# BL808 register map
File version: 0.1
Registers are access not given, no defined reset value unless marked. A register's access mark holds for its fields unless they carry their own. Offsets are from the block's base; [hi:lo] are bit positions; {n}, {i} and the like mark numbered series.

## USB
Base 0x02007200
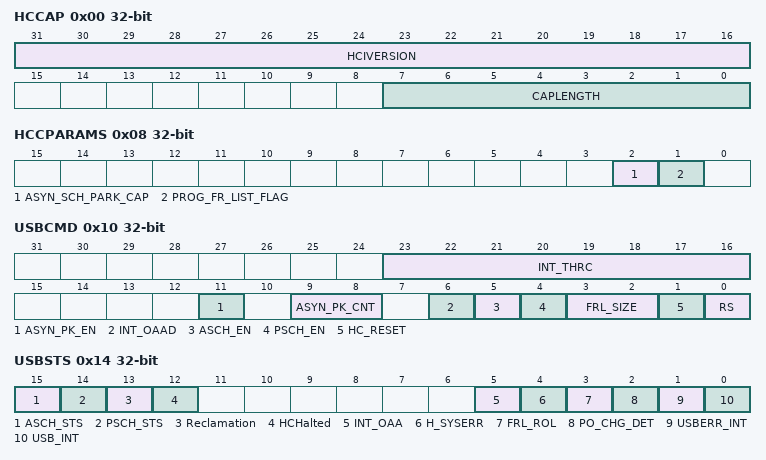
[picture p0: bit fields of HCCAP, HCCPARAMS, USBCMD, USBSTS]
0x00 HCCAP
  [31:16] HCIVERSION, [7:0] CAPLENGTH
0x04 HCSPARAMS
  [3:0] N_PORTS
0x08 HCCPARAMS
  [2] ASYN_SCH_PARK_CAP, [1] PROG_FR_LIST_FLAG
0x10 USBCMD
  [23:16] INT_THRC, [11] ASYN_PK_EN, [9:8] ASYN_PK_CNT, [6] INT_OAAD, [5] ASCH_EN, [4] PSCH_EN, [3:2] FRL_SIZE, [1] HC_RESET, [0] RS
0x14 USBSTS
  [15] ASCH_STS, [14] PSCH_STS, [13] Reclamation, [12] HCHalted, [5] INT_OAA, [4] H_SYSERR, [3] FRL_ROL, [2] PO_CHG_DET, [1] USBERR_INT, [0] USB_INT
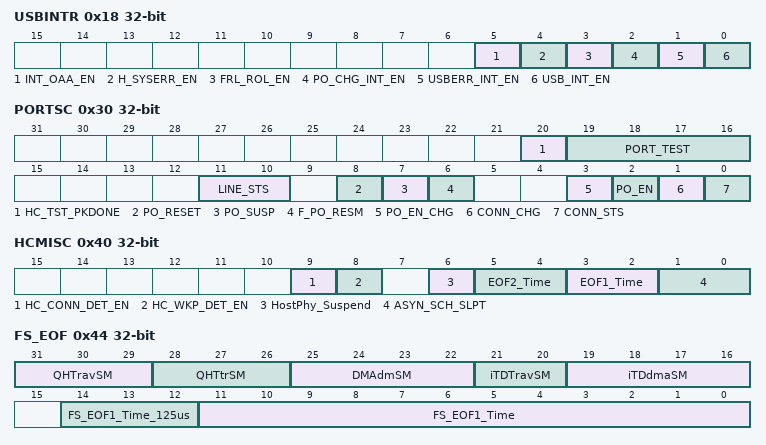
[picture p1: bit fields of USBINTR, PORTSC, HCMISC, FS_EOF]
0x18 USBINTR
  [5] INT_OAA_EN, [4] H_SYSERR_EN, [3] FRL_ROL_EN, [2] PO_CHG_INT_EN, [1] USBERR_INT_EN, [0] USB_INT_EN
0x1C FRINDEX
  [13:0] FRINDEX
0x24 PERIODICLISTBASE
  [31:12] PERI_BASADR
0x28 ASYNCLISTADDR
  [31:5] Async_ladr
0x30 PORTSC
  [20] HC_TST_PKDONE, [19:16] PORT_TEST, [11:10] LINE_STS, [8] PO_RESET, [7] PO_SUSP, [6] F_PO_RESM, [3] PO_EN_CHG, [2] PO_EN, [1] CONN_CHG, [0] CONN_STS
0x40 HCMISC
  [9] HC_CONN_DET_EN, [8] HC_WKP_DET_EN, [6] HostPhy_Suspend, [5:4] EOF2_Time, [3:2] EOF1_Time, [1:0] ASYN_SCH_SLPT
0x44 FS_EOF
  [31:29] QHTravSM, [28:26] QHTtrSM, [25:22] DMAdmSM, [21:20] iTDTravSM, [19:16] iTDdmaSM, [14:12] FS_EOF1_Time_125us, [11:0] FS_EOF1_Time
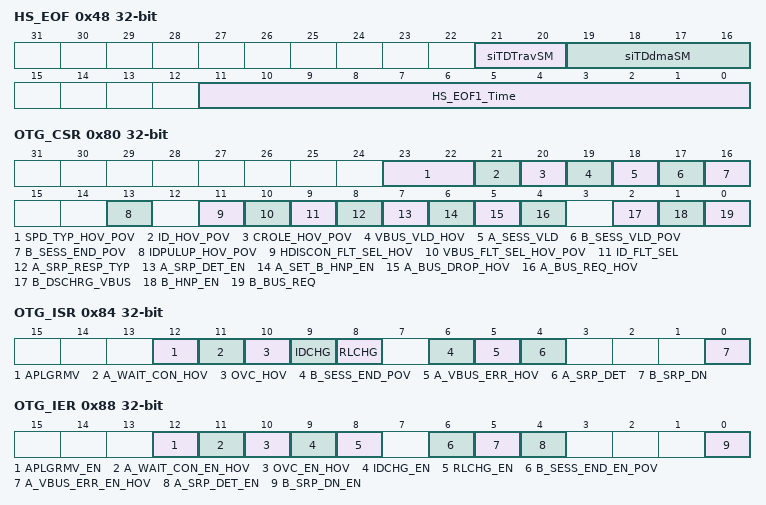
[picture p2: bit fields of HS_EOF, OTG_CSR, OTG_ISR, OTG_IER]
0x48 HS_EOF
  [21:20] siTDTravSM, [19:16] siTDdmaSM, [11:0] HS_EOF1_Time
0x80 OTG_CSR
  [23:22] SPD_TYP_HOV_POV, [21] ID_HOV_POV, [20] CROLE_HOV_POV, [19] VBUS_VLD_HOV, [18] A_SESS_VLD, [17] B_SESS_VLD_POV, [16] B_SESS_END_POV, [13] IDPULUP_HOV_POV, [11] HDISCON_FLT_SEL_HOV, [10] VBUS_FLT_SEL_HOV_POV, [9] ID_FLT_SEL, [8] A_SRP_RESP_TYP, [7] A_SRP_DET_EN, [6] A_SET_B_HNP_EN, [5] A_BUS_DROP_HOV, [4] A_BUS_REQ_HOV, [2] B_DSCHRG_VBUS, [1] B_HNP_EN, [0] B_BUS_REQ
0x84 OTG_ISR
  [12] APLGRMV, [11] A_WAIT_CON_HOV, [10] OVC_HOV, [9] IDCHG, [8] RLCHG, [6] B_SESS_END_POV, [5] A_VBUS_ERR_HOV, [4] A_SRP_DET, [0] B_SRP_DN
0x88 OTG_IER
  [12] APLGRMV_EN, [11] A_WAIT_CON_EN_HOV, [10] OVC_EN_HOV, [9] IDCHG_EN, [8] RLCHG_EN, [6] B_SESS_END_EN_POV, [5] A_VBUS_ERR_EN_HOV, [4] A_SRP_DET_EN, [0] B_SRP_DN_EN
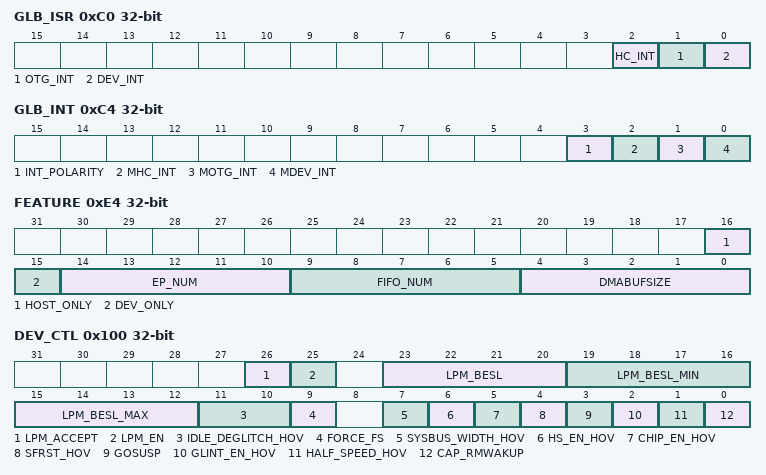
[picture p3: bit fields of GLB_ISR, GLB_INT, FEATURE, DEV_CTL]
0xC0 GLB_ISR
  [2] HC_INT, [1] OTG_INT, [0] DEV_INT
0xC4 GLB_INT
  [3] INT_POLARITY, [2] MHC_INT, [1] MOTG_INT, [0] MDEV_INT
0xE0 REVISION
  [31:0] REVISION
0xE4 FEATURE
  [16] HOST_ONLY, [15] DEV_ONLY, [14:10] EP_NUM, [9:5] FIFO_NUM, [4:0] DMABUFSIZE
0xE8 AXI_CR
  [0] AXI_SGLBST
0x100 DEV_CTL
  [26] LPM_ACCEPT, [25] LPM_EN, [23:20] LPM_BESL, [19:16] LPM_BESL_MIN, [15:12] LPM_BESL_MAX, [11:10] IDLE_DEGLITCH_HOV, [9] FORCE_FS, [7] SYSBUS_WIDTH_HOV, [6] HS_EN_HOV, [5] CHIP_EN_HOV, [4] SFRST_HOV, [3] GOSUSP, [2] GLINT_EN_HOV, [1] HALF_SPEED_HOV, [0] CAP_RMWAKUP
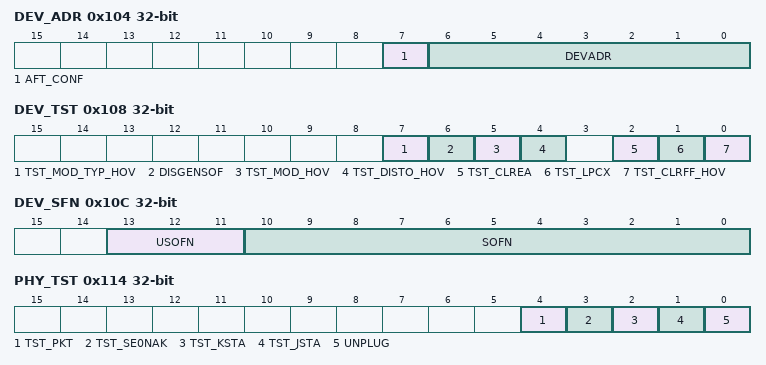
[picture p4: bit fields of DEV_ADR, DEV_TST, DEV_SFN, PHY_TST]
0x104 DEV_ADR
  [7] AFT_CONF, [6:0] DEVADR
0x108 DEV_TST
  [7] TST_MOD_TYP_HOV, [6] DISGENSOF, [5] TST_MOD_HOV, [4] TST_DISTO_HOV, [2] TST_CLREA, [1] TST_LPCX, [0] TST_CLRFF_HOV
0x10C DEV_SFN
  [13:11] USOFN, [10:0] SOFN
0x110 DEV_SMT
  [15:0] SOFMT
0x114 PHY_TST
  [4] TST_PKT, [3] TST_SE0NAK, [2] TST_KSTA, [1] TST_JSTA, [0] UNPLUG
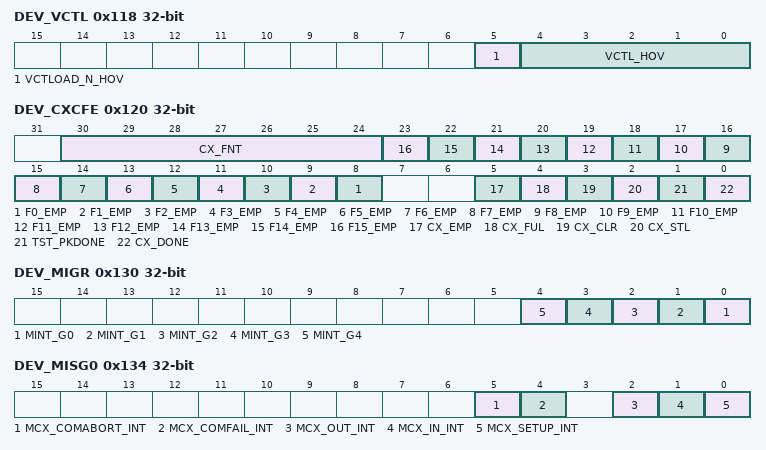
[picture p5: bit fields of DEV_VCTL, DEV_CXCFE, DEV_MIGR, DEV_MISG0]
0x118 DEV_VCTL
  [5] VCTLOAD_N_HOV, [4:0] VCTL_HOV
0x11C DEV_CXCFG
  [7:0] VSTA_HOV
0x120 DEV_CXCFE
  [30:24] CX_FNT, [n+8] F{n}_EMP (n=0..15), [5] CX_EMP, [4] CX_FUL, [3] CX_CLR, [2] CX_STL, [1] TST_PKDONE, [0] CX_DONE
0x124 DEV_ICR
  [2:0] IDLE_CNT
0x130 DEV_MIGR
  [n] MINT_G{n} (n=0..4)
0x134 DEV_MISG0
  [5] MCX_COMABORT_INT, [4] MCX_COMFAIL_INT, [2] MCX_OUT_INT, [1] MCX_IN_INT, [0] MCX_SETUP_INT
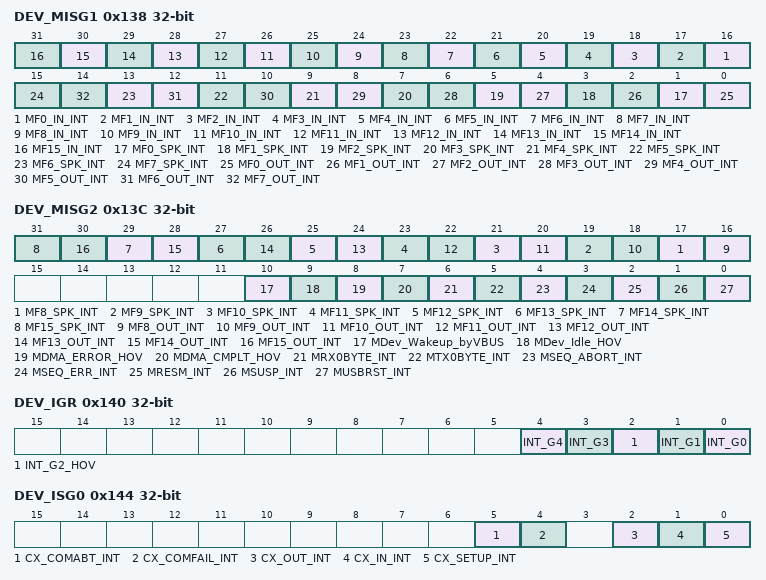
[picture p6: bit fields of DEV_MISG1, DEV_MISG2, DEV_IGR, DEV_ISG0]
0x138 DEV_MISG1
  [n+16] MF{n}_IN_INT (n=0..15), [2n+1] MF{n}_SPK_INT (n=0..7), [2n] MF{n}_OUT_INT (n=0..7)
0x13C DEV_MISG2
  [2n+1] MF{n}_SPK_INT (n=8..15), [2n] MF{n}_OUT_INT (n=8..15), [10] MDev_Wakeup_byVBUS, [9] MDev_Idle_HOV, [8] MDMA_ERROR_HOV, [7] MDMA_CMPLT_HOV, [6] MRX0BYTE_INT, [5] MTX0BYTE_INT, [4] MSEQ_ABORT_INT, [3] MSEQ_ERR_INT, [2] MRESM_INT, [1] MSUSP_INT, [0] MUSBRST_INT
0x140 DEV_IGR
  [4] INT_G4, [3] INT_G3, [2] INT_G2_HOV, [1] INT_G1, [0] INT_G0
0x144 DEV_ISG0
  [5] CX_COMABT_INT, [4] CX_COMFAIL_INT, [2] CX_OUT_INT, [1] CX_IN_INT, [0] CX_SETUP_INT
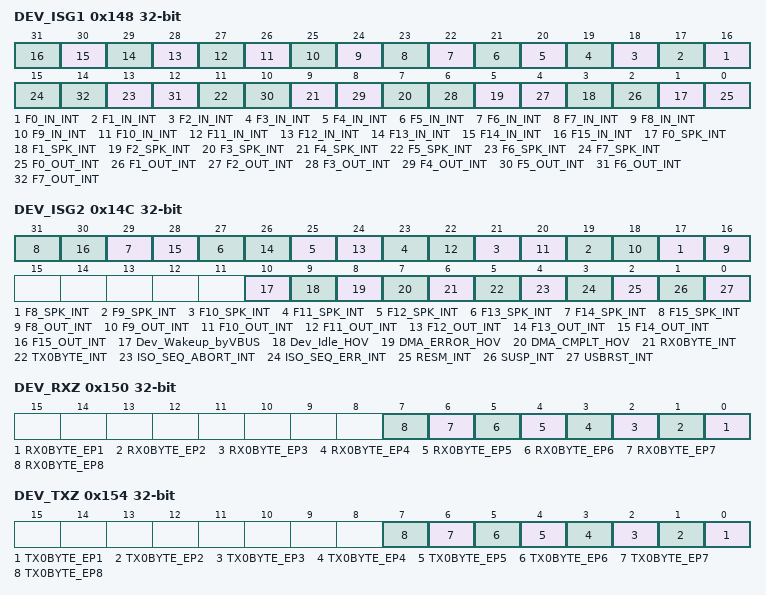
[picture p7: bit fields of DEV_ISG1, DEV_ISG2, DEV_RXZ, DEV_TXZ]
0x148 DEV_ISG1
  [n+16] F{n}_IN_INT (n=0..15), [2n+1] F{n}_SPK_INT (n=0..7), [2n] F{n}_OUT_INT (n=0..7)
0x14C DEV_ISG2
  [2n+1] F{n}_SPK_INT (n=8..15), [2n] F{n}_OUT_INT (n=8..15), [10] Dev_Wakeup_byVBUS, [9] Dev_Idle_HOV, [8] DMA_ERROR_HOV, [7] DMA_CMPLT_HOV, [6] RX0BYTE_INT, [5] TX0BYTE_INT, [4] ISO_SEQ_ABORT_INT, [3] ISO_SEQ_ERR_INT, [2] RESM_INT, [1] SUSP_INT, [0] USBRST_INT
0x150 DEV_RXZ
  [n-1] RX0BYTE_EP{n} (n=1..8)
0x154 DEV_TXZ
  [n-1] TX0BYTE_EP{n} (n=1..8)
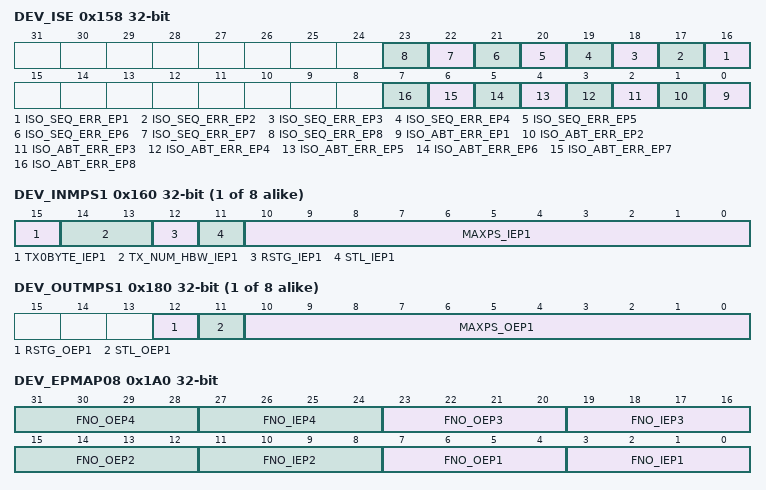
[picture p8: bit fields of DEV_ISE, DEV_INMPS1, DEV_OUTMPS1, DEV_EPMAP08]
0x158 DEV_ISE
  [n+15] ISO_SEQ_ERR_EP{n} (n=1..8), [n-1] ISO_ABT_ERR_EP{n} (n=1..8)
{0x15C+4i} DEV_INMPS{i} (i=1..8)
  [15] TX0BYTE_IEP{i}, [14:13] TX_NUM_HBW_IEP{i}, [12] RSTG_IEP{i}, [11] STL_IEP{i}, [10:0] MAXPS_IEP{i}
{0x17C+4i} DEV_OUTMPS{i} (i=1..8)
  [12] RSTG_OEP{i}, [11] STL_OEP{i}, [10:0] MAXPS_OEP{i}
0x1A0 DEV_EPMAP08
  [8n-1:8n-4] FNO_OEP{n} (n=1..4), [8n-5:8n-8] FNO_IEP{n} (n=1..4)
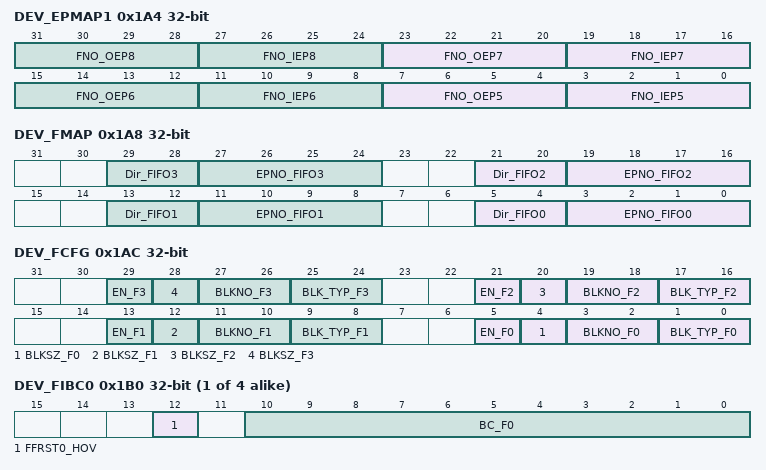
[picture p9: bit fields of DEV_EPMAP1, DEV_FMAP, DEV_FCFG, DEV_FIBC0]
0x1A4 DEV_EPMAP1
  [8n-33:8n-36] FNO_OEP{n} (n=5..8), [8n-37:8n-40] FNO_IEP{n} (n=5..8)
0x1A8 DEV_FMAP
  [8n+5:8n+4] Dir_FIFO{n} (n=0..3), [8n+3:8n] EPNO_FIFO{n} (n=0..3)
0x1AC DEV_FCFG
  [8n+5] EN_F{n} (n=0..3), [8n+4] BLKSZ_F{n} (n=0..3), [8n+3:8n+2] BLKNO_F{n} (n=0..3), [8n+1:8n] BLK_TYP_F{n} (n=0..3)
{0x1B0+4i} DEV_FIBC{i} (i=0..3)
  [12] FFRST{i}_HOV, [10:0] BC_F{i}
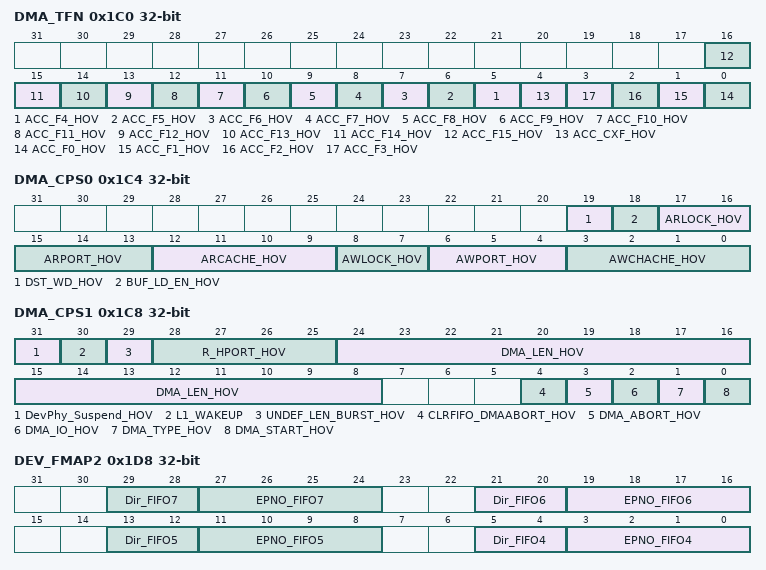
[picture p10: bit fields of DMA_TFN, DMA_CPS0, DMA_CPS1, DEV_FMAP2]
0x1C0 DMA_TFN
  [n+1] ACC_F{n}_HOV (n=4..15), [4] ACC_CXF_HOV, [n] ACC_F{n}_HOV (n=0..3)
0x1C4 DMA_CPS0
  [19] DST_WD_HOV, [18] BUF_LD_EN_HOV, [17:16] ARLOCK_HOV, [15:13] ARPORT_HOV, [12:9] ARCACHE_HOV, [8:7] AWLOCK_HOV, [6:4] AWPORT_HOV, [3:0] AWCHACHE_HOV
0x1C8 DMA_CPS1
  [31] DevPhy_Suspend_HOV, [30] L1_WAKEUP, [29] UNDEF_LEN_BURST_HOV, [28:25] R_HPORT_HOV, [24:8] DMA_LEN_HOV, [4] CLRFIFO_DMAABORT_HOV, [3] DMA_ABORT_HOV, [2] DMA_IO_HOV, [1] DMA_TYPE_HOV, [0] DMA_START_HOV
0x1CC DMA_CPS2
  [31:0] DMA_MADDR_HOV
0x1D0 DMA_CPS3
  [31:0] SETUP_CMD_RPORT
0x1D4 DMA_CPS4
0x1D8 DEV_FMAP2
  [8n-27:8n-28] Dir_FIFO{n} (n=4..7), [8n-29:8n-32] EPNO_FIFO{n} (n=4..7)
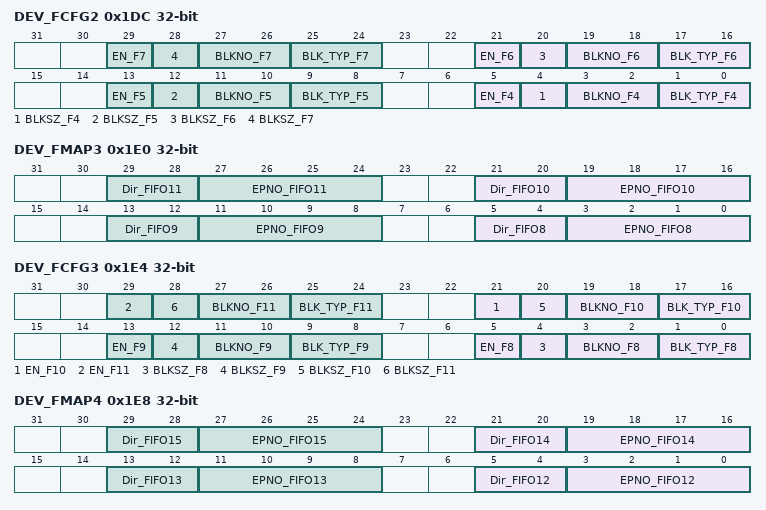
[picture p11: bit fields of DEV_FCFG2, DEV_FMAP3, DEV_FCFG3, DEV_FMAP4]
0x1DC DEV_FCFG2
  [8n-27] EN_F{n} (n=4..7), [8n-28] BLKSZ_F{n} (n=4..7), [8n-29:8n-30] BLKNO_F{n} (n=4..7), [8n-31:8n-32] BLK_TYP_F{n} (n=4..7)
0x1E0 DEV_FMAP3
  [8n-59:8n-60] Dir_FIFO{n} (n=8..11), [8n-61:8n-64] EPNO_FIFO{n} (n=8..11)
0x1E4 DEV_FCFG3
  [8n-59] EN_F{n} (n=8..11), [8n-60] BLKSZ_F{n} (n=8..11), [8n-61:8n-62] BLKNO_F{n} (n=8..11), [8n-63:8n-64] BLK_TYP_F{n} (n=8..11)
0x1E8 DEV_FMAP4
  [8n-91:8n-92] Dir_FIFO{n} (n=12..15), [8n-93:8n-96] EPNO_FIFO{n} (n=12..15)
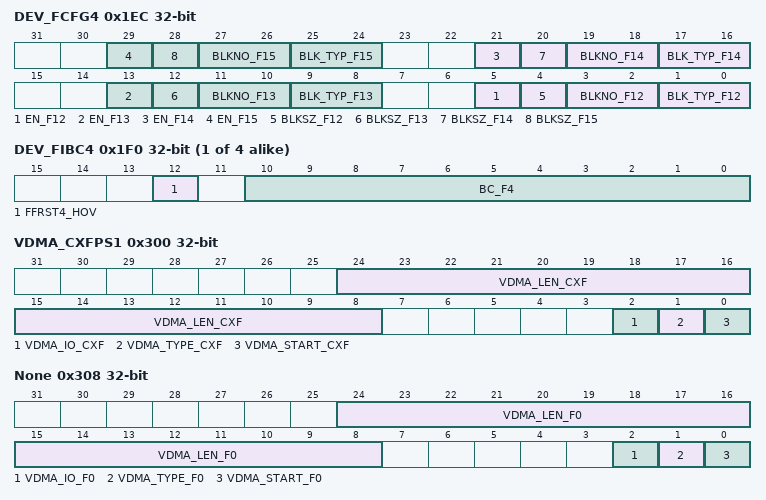
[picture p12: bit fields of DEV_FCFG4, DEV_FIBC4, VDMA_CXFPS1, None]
0x1EC DEV_FCFG4
  [8n-91] EN_F{n} (n=12..15), [8n-92] BLKSZ_F{n} (n=12..15), [8n-93:8n-94] BLKNO_F{n} (n=12..15), [8n-95:8n-96] BLK_TYP_F{n} (n=12..15)
{0x1E0+4i} DEV_FIBC{i} (i=4..7)
  [12] FFRST{i}_HOV, [10:0] BC_F{i}
0x300 VDMA_CXFPS1
  [24:8] VDMA_LEN_CXF, [2] VDMA_IO_CXF, [1] VDMA_TYPE_CXF, [0] VDMA_START_CXF
0x304 None
  [31:0] VDMA_MADDR_CXF
0x308 None
  [24:8] VDMA_LEN_F0, [2] VDMA_IO_F0, [1] VDMA_TYPE_F0, [0] VDMA_START_F0
{0x30C+8i} VDMA_F{i}PS2 (i=0..3)
  [31:0] VDMA_MADDR_F{i}
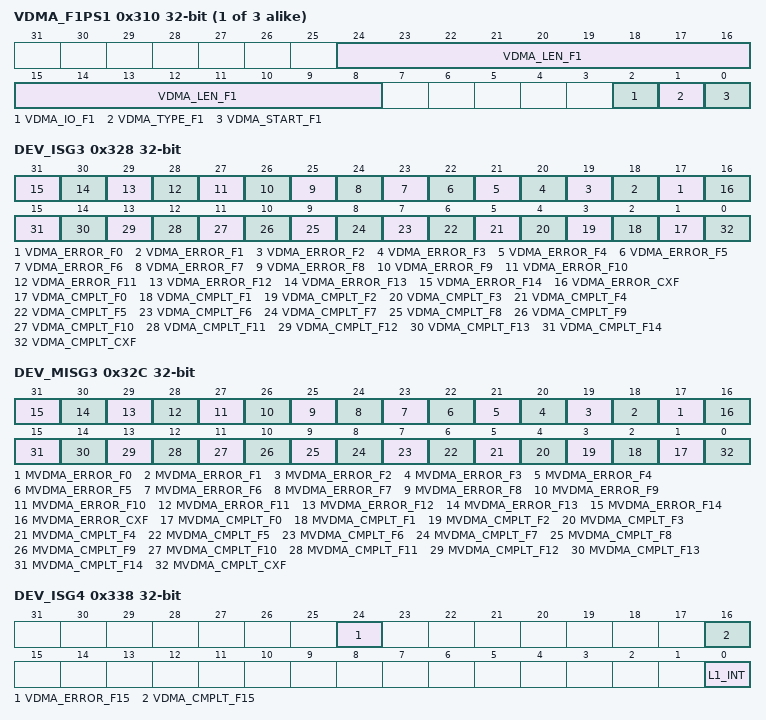
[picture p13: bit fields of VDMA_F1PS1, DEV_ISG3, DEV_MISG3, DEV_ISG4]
{0x308+8i} VDMA_F{i}PS1 (i=1..3)
  [24:8] VDMA_LEN_F{i}, [2] VDMA_IO_F{i}, [1] VDMA_TYPE_F{i}, [0] VDMA_START_F{i}
0x328 DEV_ISG3
  [n+17] VDMA_ERROR_F{n} (n=0..14), [16] VDMA_ERROR_CXF, [n+1] VDMA_CMPLT_F{n} (n=0..14), [0] VDMA_CMPLT_CXF
0x32C DEV_MISG3
  [n+17] MVDMA_ERROR_F{n} (n=0..14), [16] MVDMA_ERROR_CXF, [n+1] MVDMA_CMPLT_F{n} (n=0..14), [0] MVDMA_CMPLT_CXF
0x330 VDMA_CTRL
  [0] VDMA_EN
0x334 LPM_CAP
  [0] LPM_WAKEUP_EN
0x338 DEV_ISG4
  [24] VDMA_ERROR_F15, [16] VDMA_CMPLT_F15, [0] L1_INT
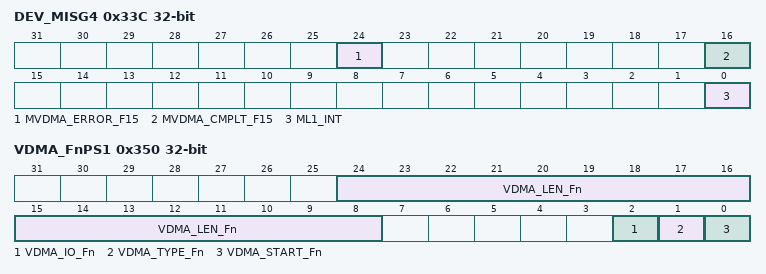
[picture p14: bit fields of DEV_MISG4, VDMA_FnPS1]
0x33C DEV_MISG4
  [24] MVDMA_ERROR_F15, [16] MVDMA_CMPLT_F15, [0] ML1_INT
0x350 VDMA_FnPS1
  [24:8] VDMA_LEN_Fn, [2] VDMA_IO_Fn, [1] VDMA_TYPE_Fn, [0] VDMA_START_Fn
0x354 VDMA_FnPS2
  [31:0] VDMA_MADDR_Fn
